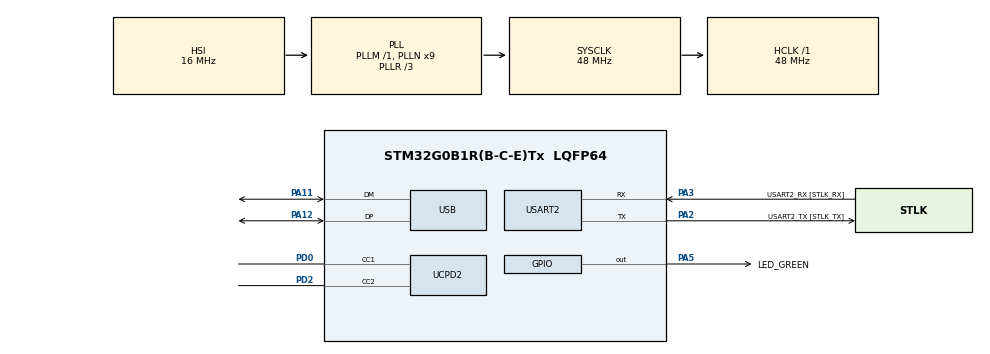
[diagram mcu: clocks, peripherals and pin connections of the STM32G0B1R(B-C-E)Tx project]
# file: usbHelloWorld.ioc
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Mcu.Family=STM32G0
Mcu.Name=STM32G0B1R(B-C-E)Tx
Mcu.Package=LQFP64
NVIC.USB_UCPD1_2_IRQn=true\:0\:0\:false\:false\:true\:true\:true\:true
PA11\ [PA9].Mode=Device
PA11\ [PA9].Signal=USB_DM
PA12\ [PA10].Mode=Device
PA12\ [PA10].Signal=USB_DP
PA13.GPIO_Label=TMS
PA13.Mode=Serial_Wire
PA13.Signal=SYS_SWDIO
PA14-BOOT0.GPIO_Label=TCK
PA14-BOOT0.Mode=Serial_Wire
PA14-BOOT0.Signal=SYS_SWCLK
PA2.GPIO_Label=USART2_TX [STLK_TX]
PA2.Mode=Asynchronous
PA2.Signal=USART2_TX
PA3.GPIO_Label=USART2_RX [STLK_RX]
PA3.Mode=Asynchronous
PA3.Signal=USART2_RX
PA5.GPIO_Label=LED_GREEN
PA5.GPIO_Speed=GPIO_SPEED_FREQ_HIGH
PA5.Signal=GPIO_Output
PC13.Mode=SYS_WakeUp1
PC13.Signal=SYS_WKUP2
PC14-OSC32_IN\ (PC14).Mode=LSE-External-Oscillator
PC14-OSC32_IN\ (PC14).Signal=RCC_OSC32_IN
PC15-OSC32_OUT\ (PC15).Mode=LSE-External-Oscillator
PC15-OSC32_OUT\ (PC15).Signal=RCC_OSC32_OUT
PD0.Mode=Sink_AllSignals
PD0.Signal=UCPD2_CC1
PD2.Mode=Sink_AllSignals
PD2.Signal=UCPD2_CC2
PF0-OSC_IN\ (PF0).GPIO_Label=MCO
PF0-OSC_IN\ (PF0).Mode=HSE-External-Clock-Source
PF0-OSC_IN\ (PF0).Signal=RCC_OSC_IN
ProjectManager.HeapSize=0x200
ProjectManager.StackSize=0x400
ProjectManager.TargetToolchain=STM32CubeIDE
RCC.ADCFreq_Value=48000000
RCC.AHBFreq_Value=48000000
RCC.CortexFreq_Value=48000000
RCC.EXTERNAL_CLOCK_VALUE=12288000
RCC.HCLKFreq_Value=48000000
RCC.HSE_VALUE=8000000
RCC.HSI48_VALUE=48000000
RCC.HSI_VALUE=16000000
RCC.PLLN=9
RCC.PLLR=RCC_PLLR_DIV3
RCC.SYSCLKFreq_VALUE=48000000
RCC.SYSCLKSource=RCC_SYSCLKSOURCE_PLLCLK
RCC.USBFreq_Value=48000000
RCC.VCOOutputFreq_Value=144000000
USART2.VirtualMode-Asynchronous=VM_ASYNC
USB_DEVICE.CLASS_NAME_FS=CDC
USB_DEVICE.PID_CDC_FS=22335
USB_DEVICE.VirtualMode=Cdc
USB_DEVICE.VirtualModeFS=Cdc_FS
VP_USB_DEVICE_VS_USB_DEVICE_CDC_FS.Mode=CDC_FS
board=NUCLEO-G0B1RE

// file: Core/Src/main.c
/* USER CODE BEGIN Header */
/**
  ******************************************************************************
  * @file           : main.c
  * @brief          : Main program body
  ******************************************************************************
  * @attention
  *
  * Copyright (c) 2023 STMicroelectronics.
  * All rights reserved.
  *
  * This software is licensed under terms that can be found in the LICENSE file
  * in the root directory of this software component.
  * If no LICENSE file comes with this software, it is provided AS-IS.
  *
  ******************************************************************************
  */
/* USER CODE END Header */
#include "main.h"
#include "usb_device.h"

/* USER CODE BEGIN Includes */
#include "usbd_cdc_if.h"
/* USER CODE END Includes */

/* USER CODE BEGIN PD */
  uint8_t RxBuffer[32];
/* USER CODE END PD */

UART_HandleTypeDef huart2;

void SystemClock_Config(void);
static void MX_GPIO_Init(void);
static void MX_USART2_UART_Init(void);
static void MX_UCPD2_Init(void);

int main(void)
{

  /* MCU Configuration--------------------------------------------------------*/

  /* Reset of all peripherals, Initializes the Flash interface and the Systick. */
  HAL_Init();

  /* Configure the system clock */
  SystemClock_Config();

  /* Initialize all configured peripherals */
  MX_GPIO_Init();
  MX_USART2_UART_Init();
  MX_USB_Device_Init();
  MX_UCPD2_Init();

  /* Infinite loop */
  /* USER CODE BEGIN WHILE */
  uint8_t HWbuffer[] = "Hello, World!\r\n";
  CDC_Transmit_FS(HWbuffer, sizeof(HWbuffer));
  while (1)
  {
    /* USER CODE END WHILE */
	  //HAL_Delay(1000);

    /* USER CODE BEGIN 3 */
	  //CDC_Receive_FS(Rxbuffer, sizeof(RxBuffer));
	  //CDC_Transmit_FS(RxBuffer, sizeof(RxBuffer));
	  HAL_Delay(10);
  }
  /* USER CODE END 3 */
}

void SystemClock_Config(void)
{
  RCC_OscInitTypeDef RCC_OscInitStruct = {0};
  RCC_ClkInitTypeDef RCC_ClkInitStruct = {0};

  /** Configure the main internal regulator output voltage
  */
  HAL_PWREx_ControlVoltageScaling(PWR_REGULATOR_VOLTAGE_SCALE1);

  /** Initializes the RCC Oscillators according to the specified parameters
  * in the RCC_OscInitTypeDef structure.
  */
  RCC_OscInitStruct.OscillatorType = RCC_OSCILLATORTYPE_HSI|RCC_OSCILLATORTYPE_HSI48;
  RCC_OscInitStruct.HSIState = RCC_HSI_ON;
  RCC_OscInitStruct.HSI48State = RCC_HSI48_ON;
  RCC_OscInitStruct.HSIDiv = RCC_HSI_DIV1;
  RCC_OscInitStruct.HSICalibrationValue = RCC_HSICALIBRATION_DEFAULT;
  RCC_OscInitStruct.PLL.PLLState = RCC_PLL_ON;
  RCC_OscInitStruct.PLL.PLLSource = RCC_PLLSOURCE_HSI;
  RCC_OscInitStruct.PLL.PLLM = RCC_PLLM_DIV1;
  RCC_OscInitStruct.PLL.PLLN = 9;
  RCC_OscInitStruct.PLL.PLLP = RCC_PLLP_DIV2;
  RCC_OscInitStruct.PLL.PLLQ = RCC_PLLQ_DIV2;
  RCC_OscInitStruct.PLL.PLLR = RCC_PLLR_DIV3;
  if (HAL_RCC_OscConfig(&RCC_OscInitStruct) != HAL_OK)
  {
    Error_Handler();
  }

  /** Initializes the CPU, AHB and APB buses clocks
  */
  RCC_ClkInitStruct.ClockType = RCC_CLOCKTYPE_HCLK|RCC_CLOCKTYPE_SYSCLK
                              |RCC_CLOCKTYPE_PCLK1;
  RCC_ClkInitStruct.SYSCLKSource = RCC_SYSCLKSOURCE_PLLCLK;
  RCC_ClkInitStruct.AHBCLKDivider = RCC_SYSCLK_DIV1;
  RCC_ClkInitStruct.APB1CLKDivider = RCC_HCLK_DIV1;

  if (HAL_RCC_ClockConfig(&RCC_ClkInitStruct, FLASH_LATENCY_1) != HAL_OK)
  {
    Error_Handler();
  }
}

static void MX_UCPD2_Init(void)
{

  LL_GPIO_InitTypeDef GPIO_InitStruct = {0};

  /* Peripheral clock enable */
  LL_APB1_GRP1_EnableClock(LL_APB1_GRP1_PERIPH_UCPD2);

  LL_IOP_GRP1_EnableClock(LL_IOP_GRP1_PERIPH_GPIOD);
  /**UCPD2 GPIO Configuration
  PD0   ------> UCPD2_CC1
  PD2   ------> UCPD2_CC2
  */
  GPIO_InitStruct.Pin = LL_GPIO_PIN_0;
  GPIO_InitStruct.Mode = LL_GPIO_MODE_ANALOG;
  GPIO_InitStruct.Pull = LL_GPIO_PULL_NO;
  LL_GPIO_Init(GPIOD, &GPIO_InitStruct);

  GPIO_InitStruct.Pin = LL_GPIO_PIN_2;
  GPIO_InitStruct.Mode = LL_GPIO_MODE_ANALOG;
  GPIO_InitStruct.Pull = LL_GPIO_PULL_NO;
  LL_GPIO_Init(GPIOD, &GPIO_InitStruct);

  /* UCPD2 interrupt Init */
  NVIC_SetPriority(USB_UCPD1_2_IRQn, 0);
  NVIC_EnableIRQ(USB_UCPD1_2_IRQn);

}

static void MX_USART2_UART_Init(void)
{

  huart2.Instance = USART2;
  huart2.Init.BaudRate = 115200;
  huart2.Init.WordLength = UART_WORDLENGTH_8B;
  huart2.Init.StopBits = UART_STOPBITS_1;
  huart2.Init.Parity = UART_PARITY_NONE;
  huart2.Init.Mode = UART_MODE_TX_RX;
  huart2.Init.HwFlowCtl = UART_HWCONTROL_NONE;
  huart2.Init.OverSampling = UART_OVERSAMPLING_16;
  huart2.Init.OneBitSampling = UART_ONE_BIT_SAMPLE_DISABLE;
  huart2.Init.ClockPrescaler = UART_PRESCALER_DIV1;
  huart2.AdvancedInit.AdvFeatureInit = UART_ADVFEATURE_NO_INIT;
  if (HAL_UART_Init(&huart2) != HAL_OK)
  {
    Error_Handler();
  }
  if (HAL_UARTEx_SetTxFifoThreshold(&huart2, UART_TXFIFO_THRESHOLD_1_8) != HAL_OK)
  {
    Error_Handler();
  }
  if (HAL_UARTEx_SetRxFifoThreshold(&huart2, UART_RXFIFO_THRESHOLD_1_8) != HAL_OK)
  {
    Error_Handler();
  }
  if (HAL_UARTEx_DisableFifoMode(&huart2) != HAL_OK)
  {
    Error_Handler();
  }

}

static void MX_GPIO_Init(void)
{
  GPIO_InitTypeDef GPIO_InitStruct = {0};

  /* GPIO Ports Clock Enable */
  __HAL_RCC_GPIOC_CLK_ENABLE();
  __HAL_RCC_GPIOF_CLK_ENABLE();
  __HAL_RCC_GPIOA_CLK_ENABLE();
  __HAL_RCC_GPIOD_CLK_ENABLE();

  /*Configure GPIO pin Output Level */
  HAL_GPIO_WritePin(LED_GREEN_GPIO_Port, LED_GREEN_Pin, GPIO_PIN_RESET);

  /*Configure GPIO pin : LED_GREEN_Pin */
  GPIO_InitStruct.Pin = LED_GREEN_Pin;
  GPIO_InitStruct.Mode = GPIO_MODE_OUTPUT_PP;
  GPIO_InitStruct.Pull = GPIO_NOPULL;
  GPIO_InitStruct.Speed = GPIO_SPEED_FREQ_HIGH;
  HAL_GPIO_Init(LED_GREEN_GPIO_Port, &GPIO_InitStruct);

}

void Error_Handler(void)
{
  __disable_irq();
  while (1)
  {
  }
}
